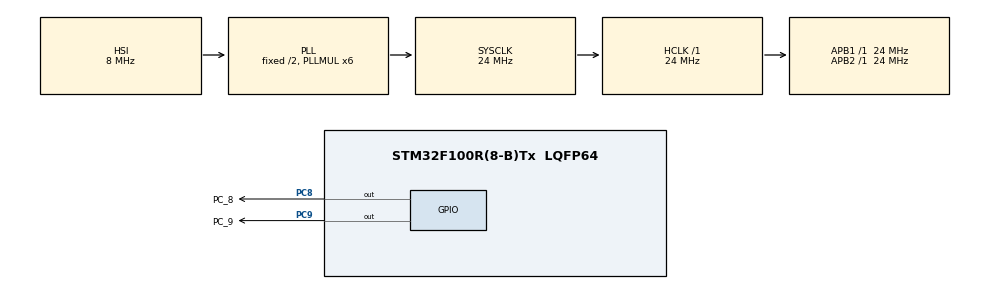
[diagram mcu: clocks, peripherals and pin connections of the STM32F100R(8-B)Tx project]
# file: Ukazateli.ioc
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Mcu.Family=STM32F1
Mcu.Name=STM32F100R(8-B)Tx
Mcu.Package=LQFP64
NVIC.PriorityGroup=NVIC_PRIORITYGROUP_4
PA13.Mode=Serial_Wire
PA13.Signal=SYS_JTMS-SWDIO
PA14.Mode=Serial_Wire
PA14.Signal=SYS_JTCK-SWCLK
PC8.GPIO_Label=PC_8
PC8.Signal=GPIO_Output
PC9.GPIO_Label=PC_9
PC9.Signal=GPIO_Output
ProjectManager.HeapSize=0x200
ProjectManager.StackSize=0x400
ProjectManager.TargetToolchain=STM32CubeIDE
RCC.AHBFreq_Value=24000000
RCC.APB1Freq_Value=24000000
RCC.APB1TimFreq_Value=24000000
RCC.APB2Freq_Value=24000000
RCC.APB2TimFreq_Value=24000000
RCC.HCLKFreq_Value=24000000
RCC.PLLMUL=RCC_PLL_MUL6
RCC.SYSCLKFreq_VALUE=24000000
RCC.SYSCLKSource=RCC_SYSCLKSOURCE_PLLCLK
board=custom

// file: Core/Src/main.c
/* USER CODE BEGIN Header */
/**
  ******************************************************************************
  * @file           : main.c
  * @brief          : Main program body
  ******************************************************************************
  * @attention
  *
  * Copyright (c) 2022 STMicroelectronics.
  * All rights reserved.
  *
  * This software is licensed under terms that can be found in the LICENSE file
  * in the root directory of this software component.
  * If no LICENSE file comes with this software, it is provided AS-IS.
  *
  ******************************************************************************
  */
/* USER CODE END Header */
#include "main.h"

/* USER CODE BEGIN Includes */

char*p;
char*q;
char*w;
//char S [] = "ABCD=/_<>[/&FGTRED642378?,::GFD";
char R [] = "0x95";

char A [] = "0x0A";
char B [] = "0x0B";
char C [] = "0x0C";
char D [] = "0x0D";
uint8_t V;
uint8_t N;
uint8_t x;
uint8_t T = 5;

uint32_t Q;
uint32_t W;
/* USER CODE END Includes */

void SystemClock_Config(void);
static void MX_GPIO_Init(void);

int main(void)
{

  /* MCU Configuration--------------------------------------------------------*/

  /* Reset of all peripherals, Initializes the Flash interface and the Systick. */
  HAL_Init();

  /* Configure the system clock */
  SystemClock_Config();

  /* Initialize all configured peripherals */
  MX_GPIO_Init();

  /* Infinite loop */
  /* USER CODE BEGIN WHILE */
  while (1)
  {

/*memcpy(A, S, 4);
p = strstr(S,"F"); //+12

q = strstr(S,"ED"); //+17

memcpy(B, S+12, 6);

w = strstr(S,"GFD");

memcpy(C, S+28, 3);
*/

//V = 0xA9;//169, 10101001
//N = 0x95;//149, 10010101

/*for(uint8_t x = 0; x < 8; x++)
{
	if(V & 0x80)
	{
	N|= 1<<x;
	}
	 V <<=1;

}*/

//Q = 0x0A << 24| 0x0B << 16| 0x0C << 8| 0x0D;

//Q = 0xABCD;

/*for(uint32_t x = 0; x < 32; x++)
{
	if(Q & 0x8000000)
	{
	W|=1<<x;
	}
	Q<<=1;
}*/

		  if((T & 0x04) && (T & 0x01)) ////////////////////////////////
		  {
			  HAL_GPIO_WritePin(GPIOC,GPIO_PIN_8 , GPIO_PIN_SET);
			 			  HAL_Delay(100);
		  }

	/*  if(T & 800)
	  {
		  HAL_GPIO_WritePin(GPIOC,GPIO_PIN_8 , GPIO_PIN_SET);
	  }

	  if(T & 4000000)
	  {
		  HAL_GPIO_WritePin(GPIOC,GPIO_PIN_8 , GPIO_PIN_SET);
	  }

	  if(T & 800000000000000)
	  {
		  HAL_GPIO_WritePin(GPIOC,GPIO_PIN_8 , GPIO_PIN_SET);
	  }*/
    /* USER CODE END WHILE */

}
}

void SystemClock_Config(void)
{
  RCC_OscInitTypeDef RCC_OscInitStruct = {0};
  RCC_ClkInitTypeDef RCC_ClkInitStruct = {0};

  /** Initializes the RCC Oscillators according to the specified parameters
  * in the RCC_OscInitTypeDef structure.
  */
  RCC_OscInitStruct.OscillatorType = RCC_OSCILLATORTYPE_HSI;
  RCC_OscInitStruct.HSIState = RCC_HSI_ON;
  RCC_OscInitStruct.HSICalibrationValue = RCC_HSICALIBRATION_DEFAULT;
  RCC_OscInitStruct.PLL.PLLState = RCC_PLL_ON;
  RCC_OscInitStruct.PLL.PLLSource = RCC_PLLSOURCE_HSI_DIV2;
  RCC_OscInitStruct.PLL.PLLMUL = RCC_PLL_MUL6;
  if (HAL_RCC_OscConfig(&RCC_OscInitStruct) != HAL_OK)
  {
    Error_Handler();
  }

  /** Initializes the CPU, AHB and APB buses clocks
  */
  RCC_ClkInitStruct.ClockType = RCC_CLOCKTYPE_HCLK|RCC_CLOCKTYPE_SYSCLK
                              |RCC_CLOCKTYPE_PCLK1|RCC_CLOCKTYPE_PCLK2;
  RCC_ClkInitStruct.SYSCLKSource = RCC_SYSCLKSOURCE_PLLCLK;
  RCC_ClkInitStruct.AHBCLKDivider = RCC_SYSCLK_DIV1;
  RCC_ClkInitStruct.APB1CLKDivider = RCC_HCLK_DIV1;
  RCC_ClkInitStruct.APB2CLKDivider = RCC_HCLK_DIV1;

  if (HAL_RCC_ClockConfig(&RCC_ClkInitStruct, FLASH_LATENCY_0) != HAL_OK)
  {
    Error_Handler();
  }
}

static void MX_GPIO_Init(void)
{
  GPIO_InitTypeDef GPIO_InitStruct = {0};

  /* GPIO Ports Clock Enable */
  __HAL_RCC_GPIOC_CLK_ENABLE();
  __HAL_RCC_GPIOA_CLK_ENABLE();

  /*Configure GPIO pin Output Level */
  HAL_GPIO_WritePin(GPIOC, PC_8_Pin|PC_9_Pin, GPIO_PIN_RESET);

  /*Configure GPIO pins : PC_8_Pin PC_9_Pin */
  GPIO_InitStruct.Pin = PC_8_Pin|PC_9_Pin;
  GPIO_InitStruct.Mode = GPIO_MODE_OUTPUT_PP;
  GPIO_InitStruct.Pull = GPIO_NOPULL;
  GPIO_InitStruct.Speed = GPIO_SPEED_FREQ_LOW;
  HAL_GPIO_Init(GPIOC, &GPIO_InitStruct);

}

void Error_Handler(void)
{
  __disable_irq();
  while (1)
  {
  }
}
